# STM32G030 register map
File version: 1.6
CPU: CM0 r0p1, little endian, MPU, no FPU, 2 interrupt priority bits
Registers are 32-bit, read-write, reset 0x0 unless marked. A register's access mark holds for its fields unless they carry their own. Offsets are from the block's base; [hi:lo] are bit positions; {n}, {i} and the like mark numbered series.

## PWR — Power control
Base 0x40007000
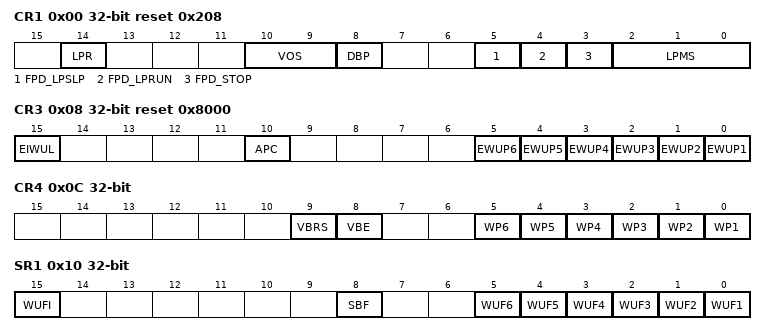
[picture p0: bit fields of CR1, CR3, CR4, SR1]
0x00 CR1 reset 0x208 — Power control register 1
  [14] LPR — Low-power run
  [10:9] VOS — Voltage scaling range selection
  [8] DBP — Disable backup domain write protection
  [5] FPD_LPSLP — Flash memory powered down during Low-power sleep mode
  [4] FPD_LPRUN — Flash memory powered down during Low-power run mode
  [3] FPD_STOP — Flash memory powered down during Stop mode
  [2:0] LPMS — Low-power mode selection
0x04 CR2 — Power control register 2
  [10] USV
0x08 CR3 reset 0x8000 — Power control register 3
  [15] EIWUL — Enable internal wakeup line
  [10] APC — Apply pull-up and pull-down configuration
  [5] EWUP6 — Enable WKUP6 wakeup pin
  [4] EWUP5 — Enable WKUP5 wakeup pin
  [n-1] EWUP{n} (n=1..4) — Enable Wakeup pin WKUP{n}
0x0C CR4 — Power control register 4
  [9] VBRS — VBAT battery charging resistor selection
  [8] VBE — VBAT battery charging enable
  [5] WP6 — WKUP6 wakeup pin polarity
  [n-1] WP{n} (n=1..5) — Wakeup pin WKUP{n} polarity
0x10 SR1 ro — Power status register 1
  [15] WUFI — Wakeup flag internal
  [8] SBF — Standby flag
  [n-1] WUF{n} (n=1..6) — Wakeup flag {n}
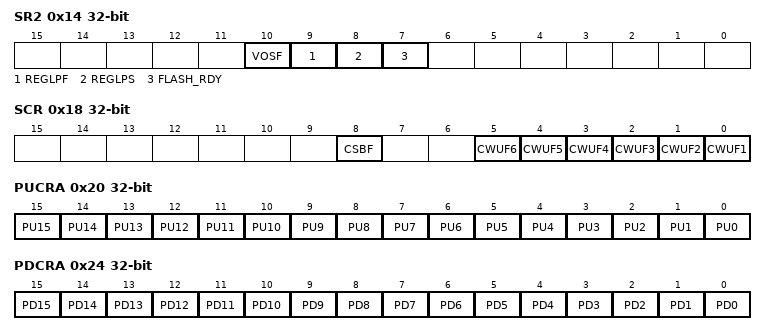
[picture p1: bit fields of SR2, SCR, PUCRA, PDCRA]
0x14 SR2 ro — Power status register 2
  [10] VOSF — Voltage scaling flag
  [9] REGLPF — Low-power regulator flag
  [8] REGLPS — Low-power regulator started
  [7] FLASH_RDY — Flash ready flag
0x18 SCR wo — Power status clear register
  [8] CSBF — Clear standby flag
  [n-1] CWUF{n} (n=1..6) — Clear wakeup flag {n}
0x20 PUCRA — Power Port A pull-up control register
  [n] PU{n} (n=0..15) — Port A pull-up bit y (y=0..15)
0x24 PDCRA — Power Port A pull-down control register
  [n] PD{n} (n=0..15) — Port A pull-down bit y (y=0..15)
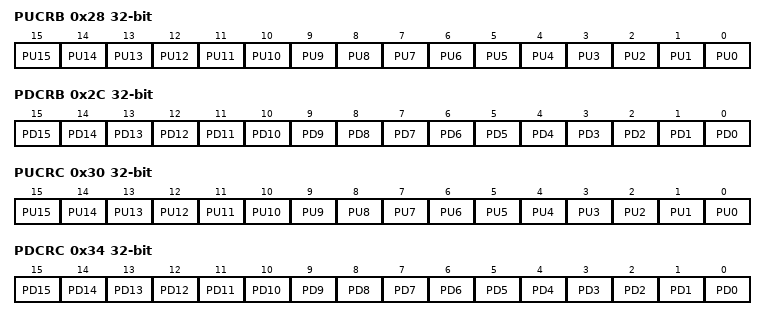
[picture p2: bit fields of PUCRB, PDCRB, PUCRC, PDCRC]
0x28 PUCRB — Power Port B pull-up control register
  [n] PU{n} (n=0..15) — Port B pull-up bit y (y=0..15)
0x2C PDCRB — Power Port B pull-down control register
  [n] PD{n} (n=0..15) — Port B pull-down bit y (y=0..15)
0x30 PUCRC — Power Port C pull-up control register
  [n] PU{n} (n=0..15) — Port C pull-up bit y (y=0..15)
0x34 PDCRC — Power Port C pull-down control register
  [n] PD{n} (n=0..15) — Port C pull-down bit y (y=0..15)
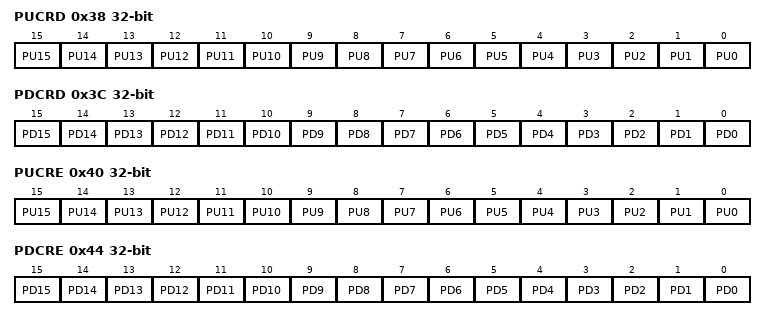
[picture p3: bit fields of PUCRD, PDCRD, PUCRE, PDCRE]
0x38 PUCRD — Power Port D pull-up control register
  [n] PU{n} (n=0..15) — Port D pull-up bit y (y=0..15)
0x3C PDCRD — Power Port D pull-down control register
  [n] PD{n} (n=0..15) — Port D pull-down bit y (y=0..15)
0x40 PUCRE — Power Port E pull-UP control register
  [n] PU{n} (n=0..15) — Port E pull-up bit y (y=0..15)
0x44 PDCRE — Power Port E pull-down control register
  [n] PD{n} (n=0..15) — Port E pull-down bit y (y=0..15)
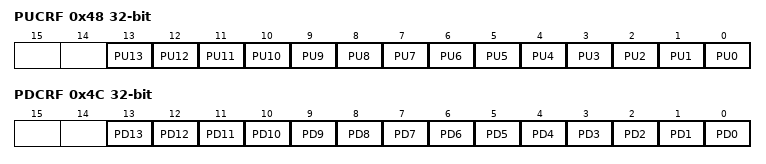
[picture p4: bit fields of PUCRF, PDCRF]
0x48 PUCRF — Power Port F pull-up control register
  [n] PU{n} (n=0..13) — Port F pull-up bit y (y=0..15)
0x4C PDCRF — Power Port F pull-down control register
  [n] PD{n} (n=0..13) — Port F pull-down bit y (y=0..15)

## DMAMUX
Base 0x40020800
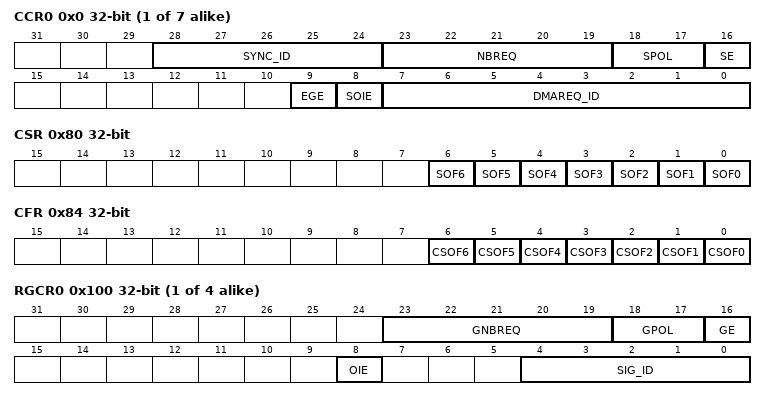
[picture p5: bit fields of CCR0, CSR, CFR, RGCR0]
{0x0+4i} CCR{i} (i=0..6) — DMA Multiplexer Channel {i} Control register
  [28:24] SYNC_ID — Synchronization input selected
  [23:19] NBREQ — Number of DMA requests to forward Defines the number of DMA requests forwarded before output event is generated. In synchronous mode, it also defines the number of DMA requests to forward after a synchronization event, then stop forwarding. The actual number of DMA requests forwarded is NBREQ+1. Note: This field can only be written when both SE and EGE bits are reset.
  [18:17] SPOL — Synchronization event type selector Defines the synchronization event on the selected synchronization input:
    0=NoEdge (No event, i.e. no synchronization nor detection); 1=RisingEdge; 2=FallingEdge; 3=BothEdges (Rising and falling edges)
  [16] SE — Synchronous operating mode enable/disable
    0=Disabled (Synchronization disabled); 1=Enabled (Synchronization enabled)
  [9] EGE — Event generation enable/disable
    0=Disabled (Event generation disabled); 1=Enabled (Event generation enabled)
  [8] SOIE — Interrupt enable at synchronization event overrun
    0=Disabled (Synchronization overrun interrupt disabled); 1=Enabled (Synchronization overrun interrupt enabled)
  [7:0] DMAREQ_ID — Input DMA request line selected
0x80 CSR ro — DMAMUX request line multiplexer interrupt channel status register
  [n] SOF{n} (n=0..6) — Synchronization Overrun Flag {n}
    0=NoSyncEvent (No synchronization event occured on a DMA request line multiplexer channel x, while the DMA request counter value is lower than NBREQ); 1=SyncEvent (Synchronization event occured on a DMA request line multiplexer channel x, while the DMA request counter value is lower than NBREQ)
0x84 CFR wo — DMAMUX request line multiplexer interrupt clear flag register
  [n] CSOF{n} (n=0..6) write-1-clears — Synchronization Clear Overrun Flag {n}
    1=Clear synchronization flag
{0x100+4i} RGCR{i} (i=0..3) — DMAMux - DMA request generator channel x control register
  [23:19] GNBREQ — Number of DMA requests to generate Defines the number of DMA requests generated after a trigger event, then stop generating. The actual number of generated DMA requests is GNBREQ+1. Note: This field can only be written when GE bit is reset.
  [18:17] GPOL — DMA request generator trigger event type selection Defines the trigger event on the selected DMA request trigger input
    0=NoEdge (No event, i.e. no detection nor generation); 1=RisingEdge; 2=FallingEdge; 3=BothEdges (Rising and falling edges)
  [16] GE — DMA request generator channel enable/disable
    0=Disabled (DMA request generation disabled); 1=Enabled (DMA request enabled)
  [8] OIE — Interrupt enable at trigger event overrun
    0=Disabled (Trigger overrun interrupt disabled); 1=Enabled (Trigger overrun interrupt enabled)
  [4:0] SIG_ID — DMA request trigger input selected
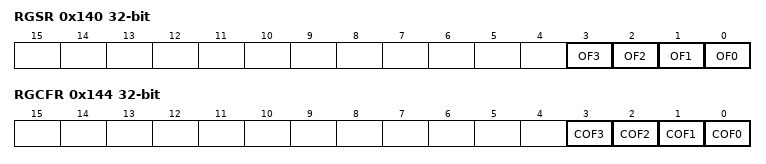
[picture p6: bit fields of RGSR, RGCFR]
0x140 RGSR ro — DMAMux - DMA request generator status register
  [n] OF{n} (n=0..3) — Generator Overrun Flag {n}
    0=NoTrigger (No new trigger event occured on DMA request generator channel x, before the request counter underrun); 1=Trigger (New trigger event occured on DMA request generator channel x, before the request counter underrun)
0x144 RGCFR wo — DMAMux - DMA request generator clear flag register
  [n] COF{n} (n=0..3) write-1-clears — Generator Clear Overrun Flag {n}
    1=Clear overrun flag
